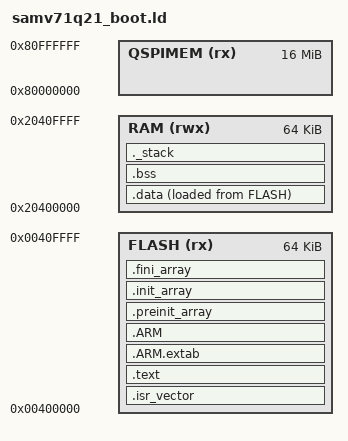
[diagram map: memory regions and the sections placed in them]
OUTPUT_FORMAT("elf32-littlearm", "elf32-littlearm", "elf32-littlearm")
OUTPUT_ARCH(arm)
SEARCH_DIR(.)

MEMORY
{
    FLASH  (rx)  : ORIGIN = 0x00400000, LENGTH = 64K
    RAM    (rwx) : ORIGIN = 0x20400000, LENGTH = 64K
    QSPIMEM (rx) : ORIGIN = 0x80000000, LENGTH = 16M
}

_stack_size = 4096;
_estack = ORIGIN(RAM) + LENGTH(RAM);

PROVIDE(_sidata = LOADADDR(.data));

SECTIONS
{
    .isr_vector :
    {
        . = ALIGN(4);
        KEEP(*(.isr_vector))
        . = ALIGN(4);
    } > FLASH

    .text :
    {
        . = ALIGN(4);
        *(.text)
        *(.text*)
        *(.rodata)
        *(.rodata*)
        *(.glue_7)
        *(.glue_7t)
        *(.eh_frame)
        KEEP(*(.init))
        KEEP(*(.fini))
        . = ALIGN(4);
        _etext = .;
    } > FLASH

    .ARM.extab :
    {
        *(.ARM.extab* .gnu.linkonce.armextab.*)
    } > FLASH

    .ARM :
    {
        __exidx_start = .;
        *(.ARM.exidx*)
        __exidx_end = .;
    } > FLASH

    .preinit_array :
    {
        PROVIDE_HIDDEN(__preinit_array_start = .);
        KEEP(*(.preinit_array*))
        PROVIDE_HIDDEN(__preinit_array_end = .);
    } > FLASH

    .init_array :
    {
        PROVIDE_HIDDEN(__init_array_start = .);
        KEEP(*(SORT(.init_array.*)))
        KEEP(*(.init_array*))
        PROVIDE_HIDDEN(__init_array_end = .);
    } > FLASH

    .fini_array :
    {
        PROVIDE_HIDDEN(__fini_array_start = .);
        KEEP(*(SORT(.fini_array.*)))
        KEEP(*(.fini_array*))
        PROVIDE_HIDDEN(__fini_array_end = .);
    } > FLASH

    .data :
    {
        . = ALIGN(4);
        _sdata = .;
        _sramfunc = .;
        KEEP(*(.ramfunc))
        KEEP(*(.ramfunc*))
        _eramfunc = .;
        *(.data)
        *(.data*)
        . = ALIGN(4);
        _edata = .;
    } > RAM AT > FLASH

    .bss :
    {
        . = ALIGN(4);
        _sbss = .;
        *(.bss)
        *(.bss*)
        *(COMMON)
        . = ALIGN(4);
        _ebss = .;
    } > RAM

    ._stack :
    {
        . = ALIGN(8);
        . = . + _stack_size;
        . = ALIGN(8);
    } > RAM

    _boot_flash_end = LOADADDR(.data) + SIZEOF(.data);
    ASSERT(_boot_flash_end <= ORIGIN(FLASH) + LENGTH(FLASH),
           "ERRO: Bootloader excede 64 KB de flash!")

    .ARM.attributes 0 :
    {
        *(.ARM.attributes)
    }
}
